# MK30D7 register map
File version: 1.6
Registers are 32-bit, read-write, reset 0x0 unless marked. A register's access mark holds for its fields unless they carry their own. Offsets are from the block's base; [hi:lo] are bit positions; {n}, {i} and the like mark numbered series; 'fields as' and 'values as' point back to an identical list.

## CAN0 — Flex Controller Area Network module
Base 0x40024000; register names take the prefix CAN0_
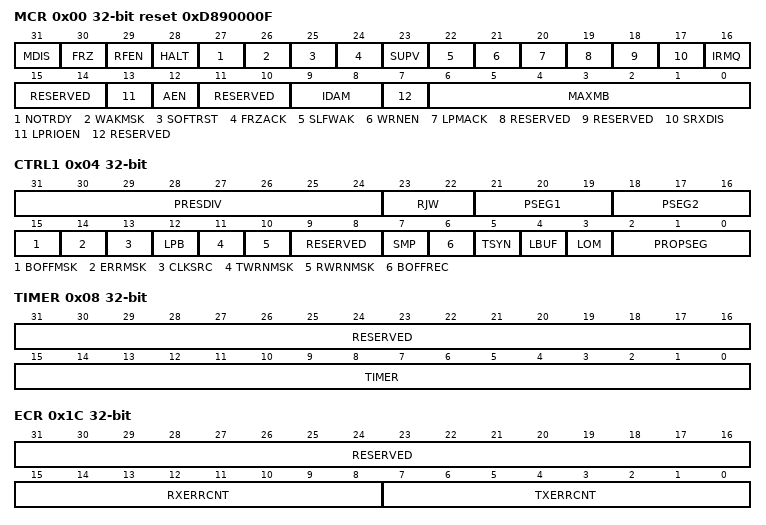
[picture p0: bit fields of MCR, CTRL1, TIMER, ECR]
0x00 MCR access per field reset 0xD890000F — Module Configuration Register
  [31] MDIS rw — Module Disable
    0=Enable the FlexCAN module; 1=Disable the FlexCAN module
  [30] FRZ rw — Freeze Enable
    0=Not enabled to enter Freeze Mode; 1=Enabled to enter Freeze Mode
  [29] RFEN rw — Rx FIFO Enable
    0=Rx FIFO not enabled; 1=Rx FIFO enabled
  [28] HALT rw — Halt FlexCAN
    0=No Freeze Mode request; 1=Enters Freeze Mode if the FRZ bit is asserted
  [27] NOTRDY ro — FlexCAN Not Ready
    0=FlexCAN module is either in Normal Mode, Listen-Only Mode or Loop-Back Mode; 1=FlexCAN module is either in Disable Mode, Stop Mode or Freeze Mode
  [26] WAKMSK rw — Wake Up Interrupt Mask
    0=Wake Up Interrupt is disabled; 1=Wake Up Interrupt is enabled
  [25] SOFTRST rw — Soft Reset
    0=No reset request; 1=Resets the registers affected by soft reset
  [24] FRZACK ro — Freeze Mode Acknowledge
    0=FlexCAN not in Freeze Mode, prescaler running; 1=FlexCAN in Freeze Mode, prescaler stopped
  [23] SUPV rw — Supervisor Mode
    0=FlexCAN is in User Mode. Affected registers allow both Supervisor and Unrestricted accesses.; 1=FlexCAN is in Supervisor Mode. Affected registers allow only Supervisor access. Unrestricted access behaves as though the access was done to an unimplemented register location.
  [22] SLFWAK rw — Self Wake Up
    0=FlexCAN Self Wake Up feature is disabled; 1=FlexCAN Self Wake Up feature is enabled
  [21] WRNEN rw — Warning Interrupt Enable
    0=TWRNINT and RWRNINT bits are zero, independent of the values in the error counters; 1=TWRNINT and RWRNINT bits are set when the respective error counter transitions from less than 96 to greater than or equal to 96
  [20] LPMACK ro — Low Power Mode Acknowledge
    0=FlexCAN is not in a low power mode; 1=FlexCAN is in a low power mode
  [19] RESERVED ro
  [18] RESERVED ro
  [17] SRXDIS rw — Self Reception Disable
    0=Self reception enabled; 1=Self reception disabled
  [16] IRMQ rw — Individual Rx Masking and Queue Enable
    0=Individual Rx masking and queue feature are disabled. For backward compatibility, the reading of C/S word locks the MB even if it is EMPTY.; 1=Individual Rx masking and queue feature are enabled
  [15:14] RESERVED ro
  [13] LPRIOEN rw — Local Priority Enable
    0=Local Priority disabled; 1=Local Priority enabled
  [12] AEN rw — Abort Enable
    0=Abort disabled; 1=Abort enabled
  [11:10] RESERVED ro
  [9:8] IDAM rw — ID Acceptance Mode
    0=Format A: One full ID (standard and extended) per ID Filter Table element; 1=Format B: Two full standard IDs or two partial 14-bit (standard and extended) IDs per ID Filter Table element; 2=Format C: Four partial 8-bit Standard IDs per ID Filter Table element; 3=Format D: All frames rejected
  [7] RESERVED ro
  [6:0] MAXMB rw — Number of the Last Message Buffer
0x04 CTRL1 access per field — Control 1 Register
  [31:24] PRESDIV rw — Prescaler Division Factor
  [23:22] RJW rw — Resync Jump Width
  [21:19] PSEG1 rw — Phase Segment 1
  [18:16] PSEG2 rw — Phase Segment 2
  [15] BOFFMSK rw — Bus Off Mask
    0=Bus Off interrupt disabled; 1=Bus Off interrupt enabled
  [14] ERRMSK rw — Error Mask
    0=Error interrupt disabled; 1=Error interrupt enabled
  [13] CLKSRC rw — CAN Engine Clock Source
    0=The CAN engine clock source is the oscillator clock. Under this condition, the oscillator clock frequency must be lower than the bus clock.; 1=The CAN engine clock source is the peripheral clock
  [12] LPB rw — Loop Back Mode
    0=Loop Back disabled; 1=Loop Back enabled
  [11] TWRNMSK rw — Tx Warning Interrupt Mask
    0=Tx Warning Interrupt disabled; 1=Tx Warning Interrupt enabled
  [10] RWRNMSK rw — Rx Warning Interrupt Mask
    0=Rx Warning Interrupt disabled; 1=Rx Warning Interrupt enabled
  [9:8] RESERVED ro
  [7] SMP rw — CAN Bit Sampling
    0=Just one sample is used to determine the bit value; 1=Three samples are used to determine the value of the received bit: the regular one (sample point) and 2 preceding samples; a majority rule is used
  [6] BOFFREC rw — Bus Off Recovery
    0=Automatic recovering from Bus Off state enabled, according to CAN Spec 2.0 part B; 1=Automatic recovering from Bus Off state disabled
  [5] TSYN rw — Timer Sync
    0=Timer Sync feature disabled; 1=Timer Sync feature enabled
  [4] LBUF rw — Lowest Buffer Transmitted First
    0=Buffer with highest priority is transmitted first; 1=Lowest number buffer is transmitted first
  [3] LOM rw — Listen-Only Mode
    0=Listen-Only Mode is deactivated; 1=FlexCAN module operates in Listen-Only Mode
  [2:0] PROPSEG rw — Propagation Segment
0x08 TIMER access per field — Free Running Timer
  [31:16] RESERVED ro
  [15:0] TIMER rw — Timer value
0x10 RXMGMASK reset 0xFFFFFFFF — Rx Mailboxes Global Mask Register
  [31:0] MG — Rx Mailboxes Global Mask Bits
    0=The corresponding bit in the filter is "don't care."; 1=The corresponding bit in the filter is checked
0x14 RX14MASK reset 0xFFFFFFFF
  [31:0] RX14M — Rx Buffer 14 Mask Bits
    values as RXMGMASK.MG
0x18 RX15MASK reset 0xFFFFFFFF
  [31:0] RX15M — Rx Buffer 15 Mask Bits
    values as RXMGMASK.MG
0x1C ECR access per field — Error Counter
  [31:16] RESERVED ro
  [15:8] RXERRCNT rw — Receive Error Counter
  [7:0] TXERRCNT rw — Transmit Error Counter
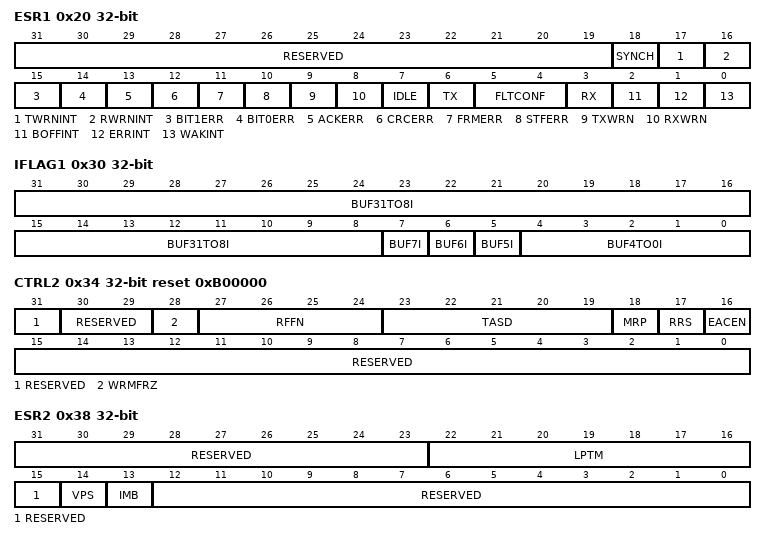
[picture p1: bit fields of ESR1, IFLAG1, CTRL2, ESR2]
0x20 ESR1 access per field — Error and Status 1 Register
  [31:19] RESERVED ro
  [18] SYNCH ro — CAN Synchronization Status
    0=FlexCAN is not synchronized to the CAN bus; 1=FlexCAN is synchronized to the CAN bus
  [17] TWRNINT rw — Tx Warning Interrupt Flag
    0=No such occurrence; 1=The Tx error counter transitioned from less than 96 to greater than or equal to 96
  [16] RWRNINT rw — Rx Warning Interrupt Flag
    0=No such occurrence; 1=The Rx error counter transitioned from less than 96 to greater than or equal to 96
  [15] BIT1ERR ro — Bit1 Error
    0=No such occurrence; 1=At least one bit sent as recessive is received as dominant
  [14] BIT0ERR ro — Bit0 Error
    0=No such occurrence; 1=At least one bit sent as dominant is received as recessive
  [13] ACKERR ro — Acknowledge Error
    0=No such occurrence; 1=An ACK error occurred since last read of this register
  [12] CRCERR ro — Cyclic Redundancy Check Error
    0=No such occurrence; 1=A CRC error occurred since last read of this register
  [11] FRMERR ro — Form Error
    0=No such occurrence; 1=A Form Error occurred since last read of this register
  [10] STFERR ro — Stuffing Error
    0=No such occurrence; 1=A Stuffing Error occurred since last read of this register
  [9] TXWRN ro — TX Error Warning
    0=No such occurrence; 1=TXERRCNT is greater than or equal to 96
  [8] RXWRN ro — Rx Error Warning
    0=No such occurrence; 1=RXERRCNT is greater than or equal to 96
  [7] IDLE ro
    0=No such occurrence; 1=CAN bus is now IDLE
  [6] TX ro — FlexCAN in Transmission
    0=FlexCAN is not transmitting a message; 1=FlexCAN is transmitting a message
  [5:4] FLTCONF ro — Fault Confinement State
    0=Error Active; 1=Error Passive; 0b1x=Bus Off
  [3] RX ro — FlexCAN in Reception
    0=FlexCAN is not receiving a message; 1=FlexCAN is receiving a message
  [2] BOFFINT rw — 'Bus Off' Interrupt
    0=No such occurrence; 1=FlexCAN module entered 'Bus Off' state
  [1] ERRINT rw — Error Interrupt
    0=No such occurrence; 1=Indicates setting of any Error Bit in the Error and Status Register
  [0] WAKINT rw — Wake-Up Interrupt
    0=No such occurrence; 1=Indicates a recessive to dominant transition was received on the CAN bus
0x24 IMASK2 — Interrupt Masks 2 Register
  [31:0] BUFHM — Buffer MBi Mask
    0=The corresponding buffer Interrupt is disabled; 1=The corresponding buffer Interrupt is enabled
0x28 IMASK1 — Interrupt Masks 1 Register
  [31:0] BUFLM — Buffer MBi Mask
    values as IMASK2.BUFHM
0x2C IFLAG2 — Interrupt Flags 2 Register
  [31:0] BUFHI — Buffer MBi Interrupt
    0=The corresponding buffer has no occurrence of successfully completed transmission or reception; 1=The corresponding buffer has successfully completed transmission or reception
0x30 IFLAG1 — Interrupt Flags 1 Register
  [31:8] BUF31TO8I — Buffer MBi Interrupt
    values as IFLAG2.BUFHI
  [7] BUF7I — Buffer MB7 Interrupt or "Rx FIFO Overflow"
    0=No occurrence of MB7 completing transmission/reception (when MCR[RFEN]=0) or of Rx FIFO overflow (when MCR[RFEN]=1); 1=MB7 completed transmission/reception (when MCR[RFEN]=0) or Rx FIFO overflow (when MCR[RFEN]=1)
  [6] BUF6I — Buffer MB6 Interrupt or "Rx FIFO Warning"
    0=No occurrence of MB6 completing transmission/reception (when MCR[RFEN]=0) or of Rx FIFO almost full (when MCR[RFEN]=1); 1=MB6 completed transmission/reception (when MCR[RFEN]=0) or Rx FIFO almost full (when MCR[RFEN]=1)
  [5] BUF5I — Buffer MB5 Interrupt or "Frames available in Rx FIFO"
    0=No occurrence of MB5 completing transmission/reception (when MCR[RFEN]=0) or of frame(s) available in the Rx FIFO (when MCR[RFEN]=1); 1=MB5 completed transmission/reception (when MCR[RFEN]=0) or frame(s) available in the Rx FIFO (when MCR[RFEN]=1)
  [4:0] BUF4TO0I — Buffer MBi Interrupt or "reserved"
    0=The corresponding buffer has no occurrence of successfully completed transmission or reception (when MCR[RFEN]=0); 1=The corresponding buffer has successfully completed transmission or reception (when MCR[RFEN]=0)
0x34 CTRL2 access per field reset 0xB00000 — Control 2 Register
  [31] RESERVED wo
  [30:29] RESERVED ro
  [28] WRMFRZ rw — Write-Access to Memory in Freeze mode
    0=Maintain the write access restrictions; 1=Enable unrestricted write access to FlexCAN memory
  [27:24] RFFN rw — Number of Rx FIFO Filters
  [23:19] TASD rw — Tx Arbitration Start Delay
  [18] MRP rw — Mailboxes Reception Priority
    0=Matching starts from Rx FIFO and continues on Mailboxes; 1=Matching starts from Mailboxes and continues on Rx FIFO
  [17] RRS rw — Remote Request Storing
    0=Remote Response Frame is generated; 1=Remote Request Frame is stored
  [16] EACEN rw — Entire Frame Arbitration Field Comparison Enable for Rx Mailboxes
    0=Rx Mailbox filter's IDE bit is always compared and RTR is never compared despite mask bits; 1=Enables the comparison of both Rx Mailbox filter's IDE and RTR bit with their corresponding bits within the incoming frame. Mask bits do apply.
  [15:0] RESERVED ro
0x38 ESR2 ro — Error and Status 2 Register
  [31:23] RESERVED
  [22:16] LPTM — Lowest Priority Tx Mailbox
  [15] RESERVED
  [14] VPS — Valid Priority Status
    0=Contents of IMB and LPTM are invalid; 1=Contents of IMB and LPTM are valid
  [13] IMB — Inactive Mailbox
    0=If ESR2[VPS] is asserted, the ESR2[LPTM] is not an inactive Mailbox; 1=If ESR2[VPS] is asserted, there is at least one inactive Mailbox. LPTM content is the number of the first one.
  [12:0] RESERVED
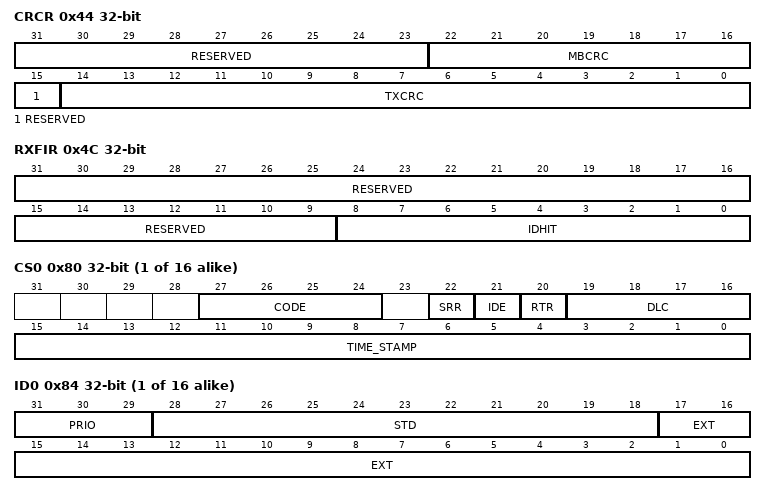
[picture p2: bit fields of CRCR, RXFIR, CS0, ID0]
0x44 CRCR ro — CRC Register
  [31:23] RESERVED
  [22:16] MBCRC — CRC Mailbox
  [15] RESERVED
  [14:0] TXCRC — CRC Transmitted
0x48 RXFGMASK reset 0xFFFFFFFF — Rx FIFO Global Mask Register
  [31:0] FGM — Rx FIFO Global Mask Bits
    values as RXMGMASK.MG
0x4C RXFIR ro reset not defined — Rx FIFO Information Register
  [31:9] RESERVED
  [8:0] IDHIT — Identifier Acceptance Filter Hit Indicator
{0x80+0x10*i} CS{i} access per field (i=0..15) — Message Buffer {i} CS Register
  [27:24] CODE rw — Reserved
  [22] SRR rw — Substitute Remote Request. Contains a fixed recessive bit.
  [21] IDE rw — ID Extended. One/zero for extended/standard format frame.
  [20] RTR rw — Remote Transmission Request. One/zero for remote/data frame.
  [19:16] DLC rw — Length of the data to be stored/transmitted.
  [15:0] TIME_STAMP rw — Free-Running Counter Time stamp. This 16-bit field is a copy of the Free-Running Timer, captured for Tx and Rx frames at the time when the beginning of the Identifier field appears on the CAN bus.
{0x84+0x10*i} ID{i} (i=0..15) — Message Buffer {i} ID Register
  [31:29] PRIO — Local priority. This 3-bit fieldis only used when LPRIO_EN bit is set in MCR and it only makes sense for Tx buffers. These bits are not transmitted. They are appended to the regular ID to define the transmission priority.
  [28:18] STD — Contains standard/extended (HIGH word) identifier of message buffer.
  [17:0] EXT — Contains extended (LOW word) identifier of message buffer.
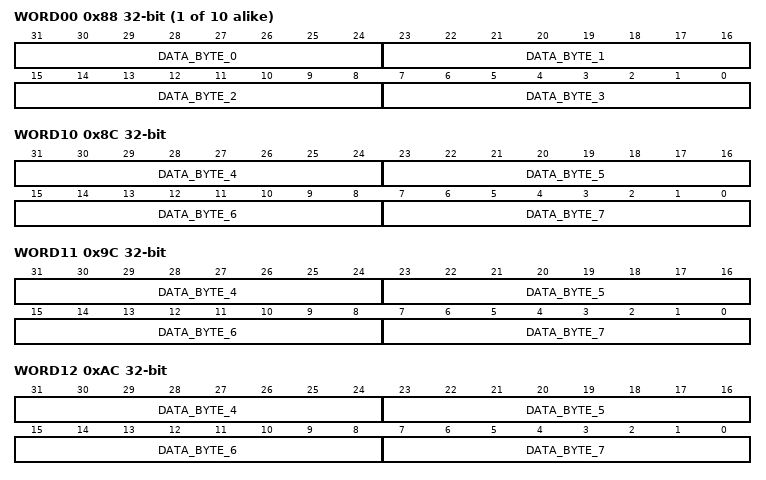
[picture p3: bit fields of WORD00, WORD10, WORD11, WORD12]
{0x88+0x10*i} WORD{i:02} (i=0..9) — Message Buffer {i} WORD0 Register
  [31-8n:24-8n] DATA_BYTE_{n} (n=0..3) — Data byte {n} of Rx/Tx frame.
0x8C WORD10 — Message Buffer 0 WORD1 Register
  [63-8n:56-8n] DATA_BYTE_{n} (n=4..7) — Data byte {n} of Rx/Tx frame.
0x9C WORD11 — Message Buffer 1 WORD1 Register
  [63-8n:56-8n] DATA_BYTE_{n} (n=4..7) — Data byte {n} of Rx/Tx frame.
0xAC WORD12 — Message Buffer 2 WORD1 Register
  [63-8n:56-8n] DATA_BYTE_{n} (n=4..7) — Data byte {n} of Rx/Tx frame.
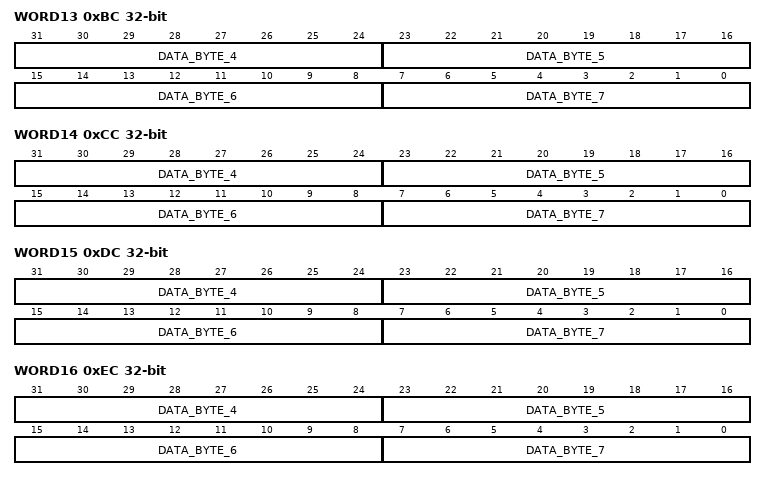
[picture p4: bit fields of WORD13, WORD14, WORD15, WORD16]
0xBC WORD13 — Message Buffer 3 WORD1 Register
  [63-8n:56-8n] DATA_BYTE_{n} (n=4..7) — Data byte {n} of Rx/Tx frame.
0xCC WORD14 — Message Buffer 4 WORD1 Register
  [63-8n:56-8n] DATA_BYTE_{n} (n=4..7) — Data byte {n} of Rx/Tx frame.
0xDC WORD15 — Message Buffer 5 WORD1 Register
  [63-8n:56-8n] DATA_BYTE_{n} (n=4..7) — Data byte {n} of Rx/Tx frame.
0xEC WORD16 — Message Buffer 6 WORD1 Register
  [63-8n:56-8n] DATA_BYTE_{n} (n=4..7) — Data byte {n} of Rx/Tx frame.
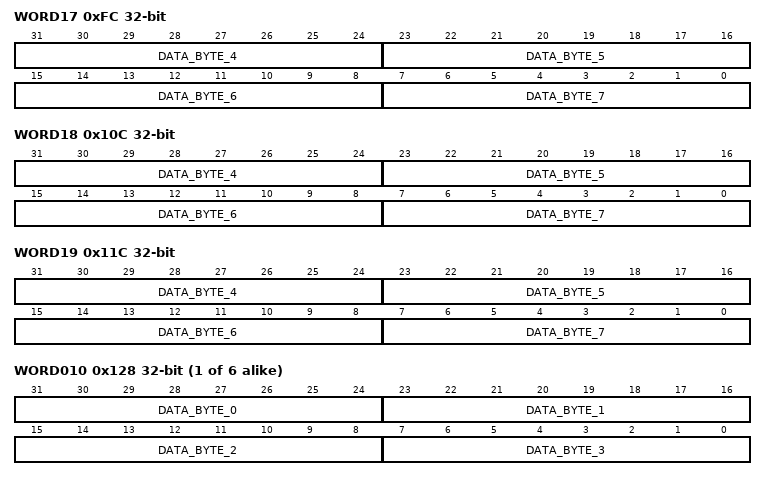
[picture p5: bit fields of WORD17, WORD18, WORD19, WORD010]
0xFC WORD17 — Message Buffer 7 WORD1 Register
  [63-8n:56-8n] DATA_BYTE_{n} (n=4..7) — Data byte {n} of Rx/Tx frame.
0x10C WORD18 — Message Buffer 8 WORD1 Register
  [63-8n:56-8n] DATA_BYTE_{n} (n=4..7) — Data byte {n} of Rx/Tx frame.
0x11C WORD19 — Message Buffer 9 WORD1 Register
  [63-8n:56-8n] DATA_BYTE_{n} (n=4..7) — Data byte {n} of Rx/Tx frame.
{0x88+0x10*i} WORD{i:03} (i=10..15) — Message Buffer {i} WORD0 Register
  [31-8n:24-8n] DATA_BYTE_{n} (n=0..3) — Data byte {n} of Rx/Tx frame.
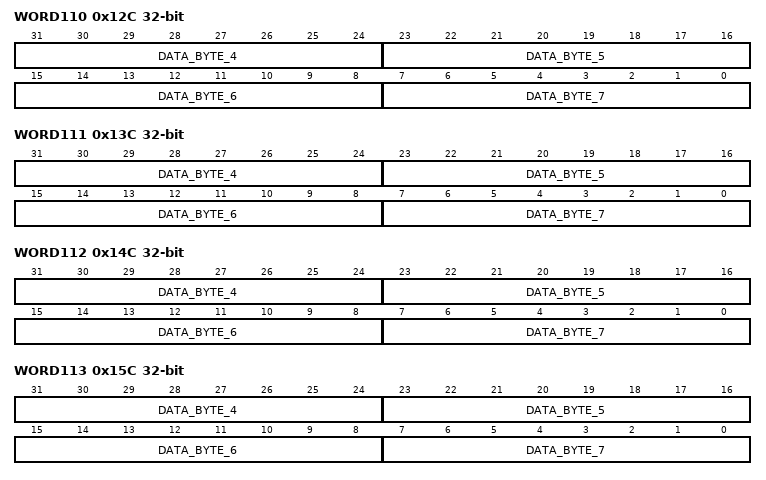
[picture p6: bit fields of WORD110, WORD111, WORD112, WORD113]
0x12C WORD110 — Message Buffer 10 WORD1 Register
  [63-8n:56-8n] DATA_BYTE_{n} (n=4..7) — Data byte {n} of Rx/Tx frame.
0x13C WORD111 — Message Buffer 11 WORD1 Register
  [63-8n:56-8n] DATA_BYTE_{n} (n=4..7) — Data byte {n} of Rx/Tx frame.
0x14C WORD112 — Message Buffer 12 WORD1 Register
  [63-8n:56-8n] DATA_BYTE_{n} (n=4..7) — Data byte {n} of Rx/Tx frame.
0x15C WORD113 — Message Buffer 13 WORD1 Register
  [63-8n:56-8n] DATA_BYTE_{n} (n=4..7) — Data byte {n} of Rx/Tx frame.
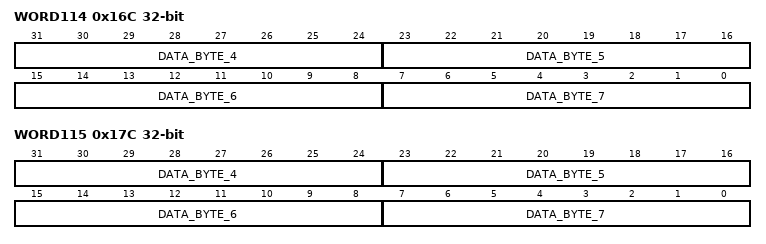
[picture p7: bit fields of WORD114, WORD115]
0x16C WORD114 — Message Buffer 14 WORD1 Register
  [63-8n:56-8n] DATA_BYTE_{n} (n=4..7) — Data byte {n} of Rx/Tx frame.
0x17C WORD115 — Message Buffer 15 WORD1 Register
  [63-8n:56-8n] DATA_BYTE_{n} (n=4..7) — Data byte {n} of Rx/Tx frame.
{0x880+4i} RXIMR{i} (i=0..15) reset not defined — Rx Individual Mask Registers
  [31:0] MI — Individual Mask Bits
    values as RXMGMASK.MG
